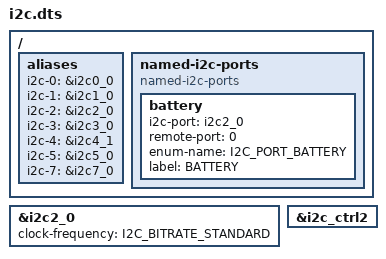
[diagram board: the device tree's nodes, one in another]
/* Copyright 2021 The Chromium OS Authors. All rights reserved.
 * Use of this source code is governed by a BSD-style license that can be
 * found in the LICENSE file.
 */

/ {
	aliases {
		i2c-0 = &i2c0_0;
		i2c-1 = &i2c1_0;
		i2c-2 = &i2c2_0;
		i2c-3 = &i2c3_0;
		i2c-4 = &i2c4_1;
		i2c-5 = &i2c5_0;
		i2c-7 = &i2c7_0;
	};

	named-i2c-ports {
		compatible = "named-i2c-ports";

		battery {
			i2c-port = <&i2c2_0>;
			remote-port = <0>;
			enum-name = "I2C_PORT_BATTERY";
			label = "BATTERY";
		};
	};


};

&i2c2_0 {
	status = "okay";
	clock-frequency = <I2C_BITRATE_STANDARD>;
};

&i2c_ctrl2 {
	status = "okay";
};
